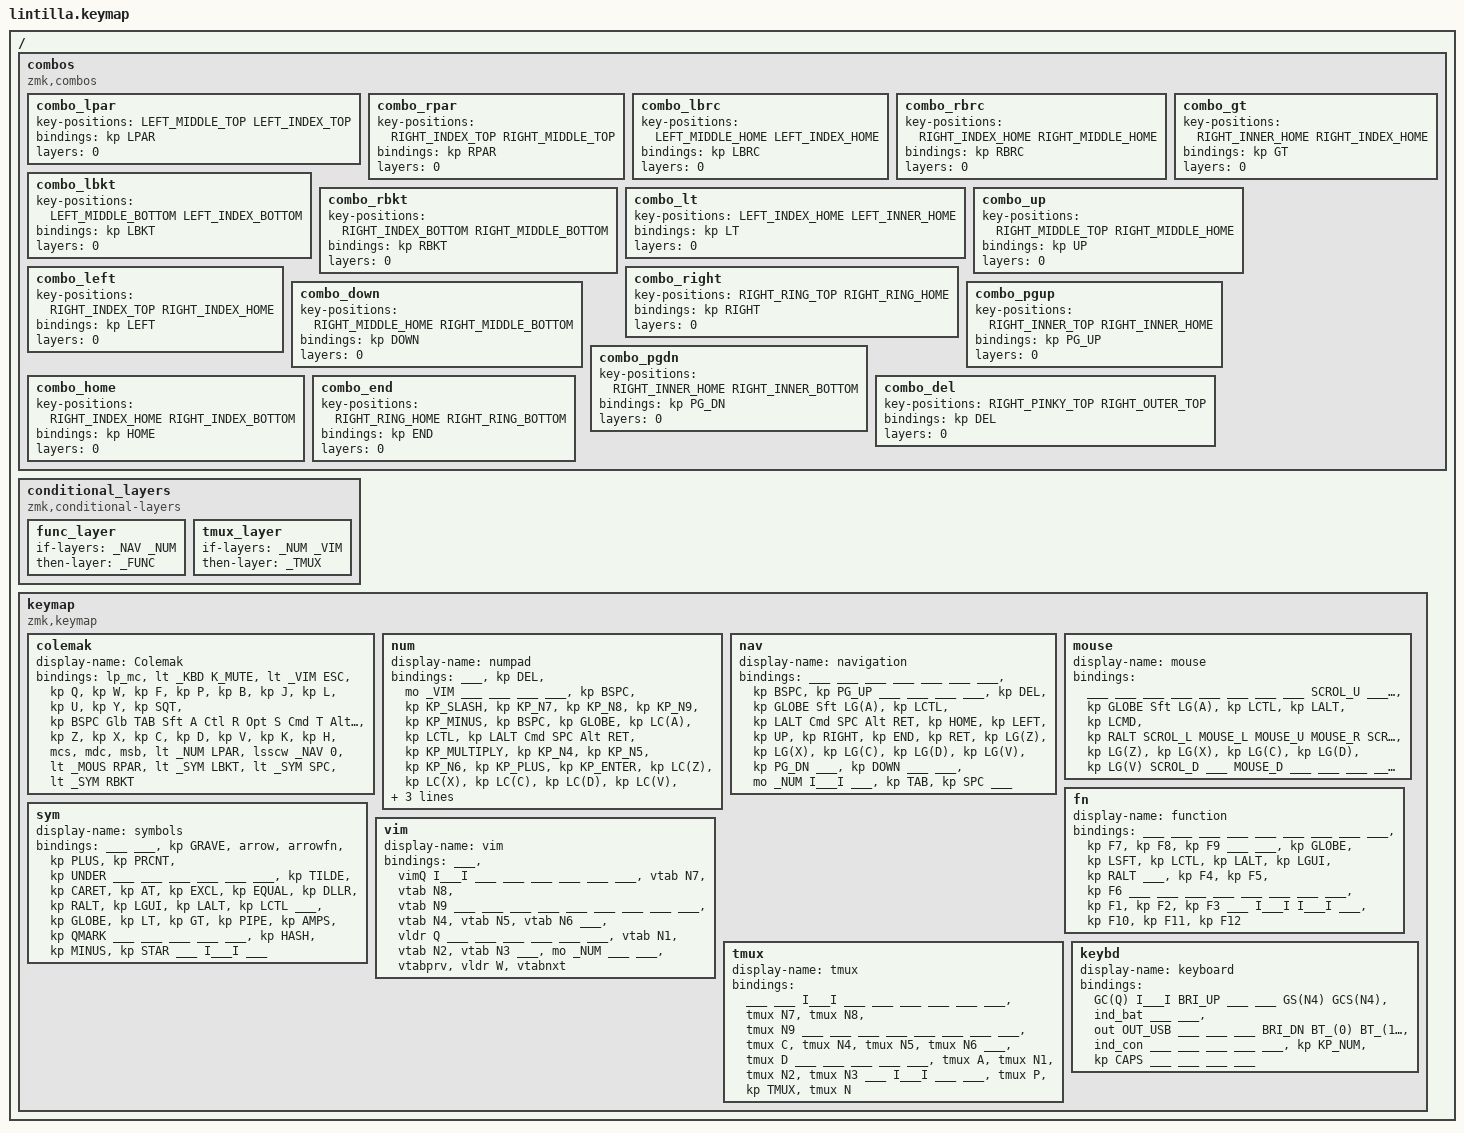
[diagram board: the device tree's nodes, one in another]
#include <behaviors.dtsi>
#include <dt-bindings/zmk/bt.h>
#include <dt-bindings/zmk/keys.h>
#include <dt-bindings/zmk/outputs.h>
#include <dt-bindings/zmk/pointing.h>
#include <behaviors/rgbled_widget.dtsi>
#include "common.keys"

#define _CLMK 0
#define _NUM  1
#define _NAV  2
#define _MOUS 3
#define _FUNC 4
#define _SYM  5
#define _VIM  6
#define _TMUX 7
#define _KBD  8

// Key Positions
//      ┏━━━━┓                                                      ┏━━━━┓
//      ┃  0 ┃                                                      ┃  1 ┃
// ┏━━━━╋━━━━╋━━━━┳━━━━┳━━━━┳━━━━┓              ┏━━━━┳━━━━┳━━━━┳━━━━╋━━━━╋━━━━┓
// ┃  2 ┃  3 ┃  4 ┃  5 ┃  6 ┃  7 ┃              ┃  8 ┃  9 ┃ 10 ┃ 11 ┃ 12 ┃ 13 ┃
// ┣━━━━╋━━━━╋━━━━╋━━━━╋━━━━╋━━━━┫              ┣━━━━╋━━━━╋━━━━╋━━━━╋━━━━╋━━━━┫
// ┃ 14 ┃ 15 ┃ 16 ┃ 17 ┃<18>┃ 19 ┃              ┃ 20 ┃<21>┃ 22 ┃ 23 ┃ 24 ┃ 25 ┃
// ┗━━━━╋━━━━╋━━━━╋━━━━╋━━━━╋━━━━┫              ┣━━━━╋━━━━╋━━━━╋━━━━╋━━━━╋━━━━┛
//      ┃ 26 ┃ 27 ┃ 28 ┃ 29 ┃ 30 ┃              ┃ 31 ┃ 32 ┃ 33 ┃ 34 ┃ 35 ┃
//      ┗━━━━┻━━━━┻━━━━┻┳━━━┻┳━━━┻┳━━━━┓  ┏━━━━┳┻━━━┳┻━━━┳┻━━━━┻━━━━┻━━━━┛
//                      ┃ 36 ┃<37>┃ 38 ┃  ┃ 39 ┃<40>┃ 41 ┃
//                      ┗━━━━┻━━━━┻━━━━┛  ┗━━━━┻━━━━┻━━━━┛
#define LEFT_MACRO 0
#define RIGHT_MACRO 1
#define LEFT_OUTER_TOP 2
#define LEFT_PINKY_TOP 3
#define LEFT_RING_TOP 4
#define LEFT_MIDDLE_TOP 5
#define LEFT_INDEX_TOP 6
#define LEFT_INNER_TOP 7
#define RIGHT_INNER_TOP 8
#define RIGHT_INDEX_TOP 9
#define RIGHT_MIDDLE_TOP 10
#define RIGHT_RING_TOP 11
#define RIGHT_PINKY_TOP 12
#define RIGHT_OUTER_TOP 13
#define LEFT_OUTER_HOME 14
#define LEFT_PINKY_HOME 15
#define LEFT_RING_HOME 16
#define LEFT_MIDDLE_HOME 17
#define LEFT_INDEX_HOME 18
#define LEFT_INNER_HOME 19
#define RIGHT_INNER_HOME 20
#define RIGHT_INDEX_HOME 21
#define RIGHT_MIDDLE_HOME 22
#define RIGHT_RING_HOME 23
#define RIGHT_PINKY_HOME 24
#define RIGHT_OUTER_HOME 25
#define LEFT_PINKY_BOTTOM 26
#define LEFT_RING_BOTTOM 27
#define LEFT_MIDDLE_BOTTOM 28
#define LEFT_INDEX_BOTTOM 29
#define LEFT_INNER_BOTTOM 30
#define RIGHT_INNER_BOTTOM 31
#define RIGHT_INDEX_BOTTOM 32
#define RIGHT_MIDDLE_BOTTOM 33
#define RIGHT_RING_BOTTOM 34
#define RIGHT_PINKY_BOTTOM 35
#define LEFT_THUMB_TUCKY 36
#define LEFT_THUMB_HOME 37
#define LEFT_THUMB_REACHY 38
#define RIGHT_THUMB_REACHY 39
#define RIGHT_THUMB_HOME 40
#define RIGHT_THUMB_TUCKY 41
/ {
    combos {
        compatible = "zmk,combos";
        combo_lpar {
            key-positions = <LEFT_MIDDLE_TOP LEFT_INDEX_TOP>;
            bindings = <&kp LPAR>;
            layers = <0>;
        };
        combo_rpar {
            key-positions = <RIGHT_INDEX_TOP RIGHT_MIDDLE_TOP>;
            bindings = <&kp RPAR>;
            layers = <0>;
        };
        combo_lbrc {
            key-positions = <LEFT_MIDDLE_HOME LEFT_INDEX_HOME>;
            bindings = <&kp LBRC>;
            layers = <0>;
        };
        combo_rbrc {
            key-positions = <RIGHT_INDEX_HOME RIGHT_MIDDLE_HOME>;
            bindings = <&kp RBRC>;
            layers = <0>;
        };
        combo_lbkt {
            key-positions = <LEFT_MIDDLE_BOTTOM LEFT_INDEX_BOTTOM>;
            bindings = <&kp LBKT>;
            layers = <0>;
        };
        combo_rbkt {
            key-positions = <RIGHT_INDEX_BOTTOM RIGHT_MIDDLE_BOTTOM>;
            bindings = <&kp RBKT>;
            layers = <0>;
        };
        combo_lt {
            key-positions = <LEFT_INDEX_HOME LEFT_INNER_HOME>;
            bindings = <&kp LT>;
            layers = <0>;
        };
        combo_gt {
            key-positions = <RIGHT_INNER_HOME RIGHT_INDEX_HOME>;
            bindings = <&kp GT>;
            layers = <0>;
        };
        combo_up {
            key-positions = <RIGHT_MIDDLE_TOP RIGHT_MIDDLE_HOME>;
            bindings = <&kp UP>;
            layers = <0>;
        };
        combo_left {
            key-positions = <RIGHT_INDEX_TOP RIGHT_INDEX_HOME>;
            bindings = <&kp LEFT>;
            layers = <0>;
        };
        combo_right {
            key-positions = <RIGHT_RING_TOP RIGHT_RING_HOME>;
            bindings = <&kp RIGHT>;
            layers = <0>;
        };
        combo_down {
            key-positions = <RIGHT_MIDDLE_HOME RIGHT_MIDDLE_BOTTOM>;
            bindings = <&kp DOWN>;
            layers = <0>;
        };
        combo_pgup {
            key-positions = <RIGHT_INNER_TOP RIGHT_INNER_HOME>;
            bindings = <&kp PG_UP>;
            layers = <0>;
        };
        combo_pgdn {
            key-positions = <RIGHT_INNER_HOME RIGHT_INNER_BOTTOM>;
            bindings = <&kp PG_DN>;
            layers = <0>;
        };
        combo_home {
            key-positions = <RIGHT_INDEX_HOME RIGHT_INDEX_BOTTOM>;
            bindings = <&kp HOME>;
            layers = <0>;
        };
        combo_end {
            key-positions = <RIGHT_RING_HOME RIGHT_RING_BOTTOM>;
            bindings = <&kp END>;
            layers = <0>;
        };
        combo_del {
            key-positions = <RIGHT_PINKY_TOP RIGHT_OUTER_TOP>;
            bindings = <&kp DEL>;
            layers = <0>;
        };
    };

    conditional_layers {
        compatible = "zmk,conditional-layers";
        func_layer {
            if-layers = <_NAV _NUM>;
            then-layer = <_FUNC>;
        };
        tmux_layer {
            if-layers = <_NUM _VIM>;
            then-layer = <_TMUX>;
        };
    };

    keymap {
        compatible = "zmk,keymap";

        colemak {
//                       ┏━━━━━━━━━━━━━━━━━━━━━━━━━┓
            display-name = "Colemak"               ;
//                       ┗━━━━━━━━━━━━━━━━━━━━━━━━━┛
            bindings = <
//         ┏━━━━━━━┓                                                                                          ┏━━━━━━━┓
//         ┃LAUNCHP┃                                                                                          ┃ MUTE  ┃
            &lp_mc                                                                                          &lt _KBD K_MUTE
//         ┃MISSION┃                                                                                          ┃ keybd ┃
// ┏━━━━━━━╋━━━━━━━╋━━━━━━━┳━━━━━━━┳━━━━━━━┳━━━━━━━┓                          ┏━━━━━━━┳━━━━━━━┳━━━━━━━┳━━━━━━━╋━━━━━━━╋━━━━━━━┓
// ┃  ESC  ┃   Q   ┃   W   ┃   F   ┃   P   ┃   B   ┃                          ┃   J   ┃   L   ┃   U   ┃   Y   ┃  ' "  ┃ BKSPC ┃
&lt _VIM ESC &kp Q   &kp W   &kp F   &kp P   &kp B                              &kp J   &kp L   &kp U   &kp Y  &kp SQT &kp BSPC
// ┣━━━━━━━╋━━━━━━━╋━━━━━━━╋━━━━━━━╋━━━━━━━╋━━━━━━━┫                          ┣━━━━━━━╋━━━━━━━╋━━━━━━━╋━━━━━━━╋━━━━━━━╋━━━━━━━┫
// ┃  TAB  ┃   A   ┃   R   ┃   S   ┃   T   ┃   G   ┃                          ┃   M   ┃   N   ┃   E   ┃   I   ┃   O   ┃RETURN ┃
    Glb TAB  Sft A   Ctl R   Opt S   Cmd T   Alt G                              Alt M   Cmd N   Opt E   Ctl I   Sft O  Glb RET
// ┃ Globe ┃ Shift ┃ Ctrl  ┃  Opt  ┃  Cmd  ┃ R Alt ┃                          ┃ R Alt ┃  Cmd  ┃  Opt  ┃ Ctrl  ┃ Shift ┃ Globe ┃
// ┗━━━━━━━╋━━━━━━━╋━━━━━━━╋━━━━━━━╋━━━━━━━╋━━━━━━━┫                          ┣━━━━━━━╋━━━━━━━╋━━━━━━━╋━━━━━━━╋━━━━━━━╋━━━━━━━┛
//         ┃   Z   ┃   X   ┃   C   ┃   D   ┃   V   ┃                          ┃   K   ┃   H   ┃  , ;  ┃  . :  ┃  / \  ┃
             &kp Z   &kp X   &kp C   &kp D   &kp V                              &kp K   &kp H   &mcs    &mdc    &msb
//         ┗━━━━━━━┻━━━━━━━┻━━━━━━━┻━━━┳━━━┻━━━┳━━━┻━━━┳━━━━━━━┓  ┏━━━━━━━┳━━━┻━━━┳━━━┻━━━┳━━━┻━━━━━━━┻━━━━━━━┻━━━━━━━┛
//                                     ┃ ( num ┃ SHIFT ┃ ) mous┃  ┃  [ {  ┃ SPACE ┃  ] }  ┃
                      &lt _NUM LPAR &lsscw _NAV 0 &lt _MOUS RPAR  &lt _SYM LBKT &lt _SYM SPC &lt _SYM RBKT
//                                     ┗━━━━━━━┫  nav  ┣━━━━━━━┛  ┗━━━━━━━┫  sym  ┣━━━━━━━┛
//                                             ┗━━━━━━━┛                  ┗━━━━━━━┛
            >;
        };

        num {
//                       ┏━━━━━━━━━━━━━━━━━━━━━━━━━┓
            display-name = "numpad"                ;
//                       ┗━━━━━━━━━━━━━━━━━━━━━━━━━┛
            bindings = <
//         ┏━━━━━━━┓                                                                                          ┏━━━━━━━┓
//         ┃       ┃                                                                                          ┃  DEL  ┃
              ___                                                                                              &kp DEL
// ┏━━━━━━━╋━━━━━━━╋━━━━━━━┳━━━━━━━┳━━━━━━━┳━━━━━━━┓                          ┏━━━━━━━┳━━━━━━━┳━━━━━━━┳━━━━━━━╋━━━━━━━╋━━━━━━━┓
// ┃ tmux  ┃       ┃       ┃       ┃       ┃ BKSPC ┃                          ┃   /   ┃   7   ┃   8   ┃   9   ┃   -   ┃ BKSPC ┃
   &mo _VIM   ___     ___     ___     ___  &kp BSPC                &kp KP_SLASH &kp KP_N7 &kp KP_N8 &kp KP_N9 &kp KP_MINUS &kp BSPC
// ┣━━━━━━━╋━━━━━━━╋━━━━━━━╋━━━━━━━╋━━━━━━━╋━━━━━━━┫                          ┣━━━━━━━╋━━━━━━━╋━━━━━━━╋━━━━━━━╋━━━━━━━╋━━━━━━━┫
// ┃       ┃ CtrlA ┃       ┃       ┃ SPACE ┃RETURN ┃                          ┃   *   ┃   4   ┃   5   ┃   6   ┃   +   ┃RETURN ┃
&kp GLOBE &kp LC(A) &kp LCTL &kp LALT Cmd SPC Alt RET             &kp KP_MULTIPLY &kp KP_N4 &kp KP_N5 &kp KP_N6 &kp KP_PLUS &kp KP_ENTER
// ┃ Globe ┃       ┃ Ctrl  ┃  Opt  ┃  Cmd  ┃ R Alt ┃                          ┃       ┃       ┃       ┃       ┃       ┃       ┃
// ┗━━━━━━━╋━━━━━━━╋━━━━━━━╋━━━━━━━╋━━━━━━━╋━━━━━━━┫                          ┣━━━━━━━╋━━━━━━━╋━━━━━━━╋━━━━━━━╋━━━━━━━╋━━━━━━━┛
//         ┃ CtrlZ ┃ CtrlX ┃ CtrlC ┃ CtrlD ┃ CtrlV ┃                          ┃   :   ┃   1   ┃   2   ┃   3   ┃   =   ┃
         &kp LC(Z) &kp LC(X) &kp LC(C) &kp LC(D) &kp LC(V)              &kp COLON &kp KP_N1 &kp KP_N2 &kp KP_N3 &kp KP_EQUAL
//         ┗━━━━━━━┻━━━━━━━┻━━━━━━━┻━━━┳━━━┻━━━┳━━━┻━━━┳━━━━━━━┓  ┏━━━━━━━┳━━━┻━━━┳━━━┻━━━┳━━━┻━━━━━━━┻━━━━━━━┻━━━━━━━┛
//                                     ┃ ##### ┃       ┃       ┃  ┃   ,   ┃   0   ┃   .   ┃
                                         I___I  &mo _NAV  ___    &kp COMMA &kp KP_N0 &kp DOT
//                                     ┗━━━━━━━┫  fn   ┣━━━━━━━┛  ┗━━━━━━━┫       ┣━━━━━━━┛
//                                             ┗━━━━━━━┛                  ┗━━━━━━━┛
            >;
        };

        nav {
//                       ┏━━━━━━━━━━━━━━━━━━━━━━━━━┓
            display-name = "navigation"            ;
//                       ┗━━━━━━━━━━━━━━━━━━━━━━━━━┛
            bindings = <
//         ┏━━━━━━━┓                                                                                          ┏━━━━━━━┓
//         ┃       ┃                                                                                          ┃       ┃
              ___                                                                                                ___
// ┏━━━━━━━╋━━━━━━━╋━━━━━━━┳━━━━━━━┳━━━━━━━┳━━━━━━━┓                          ┏━━━━━━━┳━━━━━━━┳━━━━━━━┳━━━━━━━╋━━━━━━━╋━━━━━━━┓
// ┃       ┃       ┃       ┃       ┃       ┃ BKSPC ┃                          ┃ Pg Up ┃       ┃       ┃       ┃       ┃  DEL  ┃
      ___     ___     ___     ___     ___  &kp BSPC                           &kp PG_UP  ___     ___     ___     ___   &kp DEL
// ┣━━━━━━━╋━━━━━━━╋━━━━━━━╋━━━━━━━╋━━━━━━━╋━━━━━━━┫                          ┣━━━━━━━╋━━━━━━━╋━━━━━━━╋━━━━━━━╋━━━━━━━╋━━━━━━━┫
// ┃       ┃ Cmd A ┃       ┃       ┃ SPACE ┃RETURN ┃                          ┃ Home  ┃ Left  ┃  Up   ┃ Right ┃  End  ┃RETURN ┃
&kp GLOBE Sft LG(A) &kp LCTL &kp LALT Cmd SPC Alt RET                        &kp HOME &kp LEFT &kp UP &kp RIGHT &kp END &kp RET
// ┃ Globe ┃ Shift ┃ Ctrl  ┃  Opt  ┃  Cmd  ┃ R Alt ┃                          ┃       ┃       ┃       ┃       ┃       ┃       ┃
// ┗━━━━━━━╋━━━━━━━╋━━━━━━━╋━━━━━━━╋━━━━━━━╋━━━━━━━┫                          ┣━━━━━━━╋━━━━━━━╋━━━━━━━╋━━━━━━━╋━━━━━━━╋━━━━━━━┛
//         ┃ Cmd Z ┃ Cmd X ┃ Cmd C ┃ Cmd D ┃ Cmd V ┃                          ┃ Pg Dn ┃       ┃ Down  ┃       ┃       ┃
         &kp LG(Z) &kp LG(X) &kp LG(C) &kp LG(D) &kp LG(V)                    &kp PG_DN  ___   &kp DOWN  ___     ___
//         ┗━━━━━━━┻━━━━━━━┻━━━━━━━┻━━━┳━━━┻━━━┳━━━┻━━━┳━━━━━━━┓  ┏━━━━━━━┳━━━┻━━━┳━━━┻━━━┳━━━┻━━━━━━━┻━━━━━━━┻━━━━━━━┛
//                                     ┃  fn   ┃ ##### ┃       ┃  ┃  TAB  ┃ SPACE ┃       ┃
                                        &mo _NUM I___I    ___      &kp TAB &kp SPC   ___
//                                     ┗━━━━━━━┫       ┣━━━━━━━┛  ┗━━━━━━━┫       ┣━━━━━━━┛
//                                             ┗━━━━━━━┛                  ┗━━━━━━━┛
            >;
        };

        mouse {
//                       ┏━━━━━━━━━━━━━━━━━━━━━━━━━┓
            display-name = "mouse"                 ;
//                       ┗━━━━━━━━━━━━━━━━━━━━━━━━━┛
            bindings = <
//         ┏━━━━━━━┓                                                                                          ┏━━━━━━━┓
//         ┃       ┃                                                                                          ┃       ┃
              ___                                                                                                ___
// ┏━━━━━━━╋━━━━━━━╋━━━━━━━┳━━━━━━━┳━━━━━━━┳━━━━━━━┓                          ┏━━━━━━━┳━━━━━━━┳━━━━━━━┳━━━━━━━╋━━━━━━━╋━━━━━━━┓
// ┃       ┃       ┃       ┃       ┃       ┃       ┃                          ┃ScrolUp┃       ┃       ┃       ┃       ┃       ┃
      ___     ___     ___     ___     ___     ___                              SCROL_U   ___     ___     ___     ___     ___
// ┣━━━━━━━╋━━━━━━━╋━━━━━━━╋━━━━━━━╋━━━━━━━╋━━━━━━━┫                          ┣━━━━━━━╋━━━━━━━╋━━━━━━━╋━━━━━━━╋━━━━━━━╋━━━━━━━┫
// ┃       ┃ Cmd A ┃       ┃       ┃       ┃       ┃                          ┃ScrolLt┃ Left  ┃  Up   ┃ Right ┃ScrolRt┃       ┃
&kp GLOBE Sft LG(A) &kp LCTL &kp LALT &kp LCMD &kp RALT                        SCROL_L MOUSE_L MOUSE_U MOUSE_R SCROL_R   ___
// ┃ Globe ┃ Shift ┃ Ctrl  ┃  Opt  ┃  Cmd  ┃ R Alt ┃                          ┃       ┃       ┃       ┃       ┃       ┃       ┃
// ┗━━━━━━━╋━━━━━━━╋━━━━━━━╋━━━━━━━╋━━━━━━━╋━━━━━━━┫                          ┣━━━━━━━╋━━━━━━━╋━━━━━━━╋━━━━━━━╋━━━━━━━╋━━━━━━━┛
//         ┃ Cmd Z ┃ Cmd X ┃ Cmd C ┃ Cmd D ┃ Cmd V ┃                          ┃ScrolDn┃       ┃ Down  ┃       ┃       ┃
         &kp LG(Z) &kp LG(X) &kp LG(C) &kp LG(D) &kp LG(V)                     SCROL_D   ___   MOUSE_D   ___     ___
//         ┗━━━━━━━┻━━━━━━━┻━━━━━━━┻━━━┳━━━┻━━━┳━━━┻━━━┳━━━━━━━┓  ┏━━━━━━━┳━━━┻━━━┳━━━┻━━━┳━━━┻━━━━━━━┻━━━━━━━┻━━━━━━━┛
//                                     ┃       ┃       ┃ ##### ┃  ┃       ┃l click┃r click┃
                                          ___     ___    I___I       ___   CLICK_L CLICK_R
//                                     ┗━━━━━━━┫       ┣━━━━━━━┛  ┗━━━━━━━┫       ┣━━━━━━━┛
//                                             ┗━━━━━━━┛                  ┗━━━━━━━┛
            >;
        };

        fn {
//                       ┏━━━━━━━━━━━━━━━━━━━━━━━━━┓
            display-name = "function"              ;
//                       ┗━━━━━━━━━━━━━━━━━━━━━━━━━┛
            bindings = <
//         ┏━━━━━━━┓                                                                                          ┏━━━━━━━┓
//         ┃       ┃                                                                                          ┃       ┃
              ___                                                                                                ___
// ┏━━━━━━━╋━━━━━━━╋━━━━━━━┳━━━━━━━┳━━━━━━━┳━━━━━━━┓                          ┏━━━━━━━┳━━━━━━━┳━━━━━━━┳━━━━━━━╋━━━━━━━╋━━━━━━━┓
// ┃       ┃       ┃       ┃       ┃       ┃       ┃                          ┃       ┃  F7   ┃  F8   ┃  F9   ┃       ┃       ┃
      ___     ___     ___     ___     ___     ___                                ___   &kp F7  &kp F8  &kp F9    ___     ___
// ┣━━━━━━━╋━━━━━━━╋━━━━━━━╋━━━━━━━╋━━━━━━━╋━━━━━━━┫                          ┣━━━━━━━╋━━━━━━━╋━━━━━━━╋━━━━━━━╋━━━━━━━╋━━━━━━━┫
// ┃ Globe ┃ Shift ┃ Ctrl  ┃  Opt  ┃  Cmd  ┃ R Alt ┃                          ┃       ┃  F4   ┃  F5   ┃  F6   ┃       ┃       ┃
&kp GLOBE &kp LSFT &kp LCTL &kp LALT &kp LGUI &kp RALT                           ___   &kp F4  &kp F5  &kp F6    ___     ___
// ┗━━━━━━━╋━━━━━━━╋━━━━━━━╋━━━━━━━╋━━━━━━━╋━━━━━━━┫                          ┣━━━━━━━╋━━━━━━━╋━━━━━━━╋━━━━━━━╋━━━━━━━╋━━━━━━━┛
//         ┃       ┃       ┃       ┃       ┃       ┃                          ┃       ┃  F1   ┃  F2   ┃  F3   ┃       ┃
              ___     ___     ___     ___     ___                                ___   &kp F1  &kp F2  &kp F3    ___
//         ┗━━━━━━━┻━━━━━━━┻━━━━━━━┻━━━┳━━━┻━━━┳━━━┻━━━┳━━━━━━━┓  ┏━━━━━━━┳━━━┻━━━┳━━━┻━━━┳━━━┻━━━━━━━┻━━━━━━━┻━━━━━━━┛
//                                     ┃ ##### ┃ ##### ┃       ┃  ┃  F10  ┃  F11  ┃  F12  ┃
                                         I___I   I___I    ___      &kp F10 &kp F11 &kp F12
//                                     ┗━━━━━━━┫       ┣━━━━━━━┛  ┗━━━━━━━┫       ┣━━━━━━━┛
//                                             ┗━━━━━━━┛                  ┗━━━━━━━┛
            >;
        };

        sym {
//                       ┏━━━━━━━━━━━━━━━━━━━━━━━━━┓
            display-name = "symbols"               ;
//                       ┗━━━━━━━━━━━━━━━━━━━━━━━━━┛
            bindings = <
//         ┏━━━━━━━┓                                                                                          ┏━━━━━━━┓
//         ┃       ┃                                                                                          ┃       ┃
              ___                                                                                                ___
// ┏━━━━━━━╋━━━━━━━╋━━━━━━━┳━━━━━━━┳━━━━━━━┳━━━━━━━┓                          ┏━━━━━━━┳━━━━━━━┳━━━━━━━┳━━━━━━━╋━━━━━━━╋━━━━━━━┓
// ┃   `   ┃  =>   ┃()=>{|}┃   +   ┃   %   ┃   _   ┃                          ┃       ┃       ┃       ┃       ┃       ┃       ┃
&kp GRAVE &arrow &arrowfn &kp PLUS &kp PRCNT &kp UNDER                           ___     ___     ___     ___     ___     ___
// ┣━━━━━━━╋━━━━━━━╋━━━━━━━╋━━━━━━━╋━━━━━━━╋━━━━━━━┫                          ┣━━━━━━━╋━━━━━━━╋━━━━━━━╋━━━━━━━╋━━━━━━━╋━━━━━━━┫
// ┃   ~   ┃   ^   ┃   @   ┃   !   ┃   =   ┃   $   ┃                          ┃ R Alt ┃  Cmd  ┃  Opt  ┃ Ctrl  ┃       ┃ Globe ┃
&kp TILDE &kp CARET &kp AT &kp EXCL &kp EQUAL &kp DLLR                      &kp RALT &kp LGUI &kp LALT &kp LCTL  ___  &kp GLOBE
// ┗━━━━━━━╋━━━━━━━╋━━━━━━━╋━━━━━━━╋━━━━━━━╋━━━━━━━┫                          ┣━━━━━━━╋━━━━━━━╋━━━━━━━╋━━━━━━━╋━━━━━━━╋━━━━━━━┛
//         ┃   <   ┃   >   ┃   |   ┃   &   ┃   ?   ┃                          ┃       ┃       ┃       ┃       ┃       ┃
             &kp LT &kp GT &kp PIPE &kp AMPS &kp QMARK                           ___     ___     ___     ___     ___
//         ┗━━━━━━━┻━━━━━━━┻━━━━━━━┻━━━┳━━━┻━━━┳━━━┻━━━┳━━━━━━━┓  ┏━━━━━━━┳━━━┻━━━┳━━━┻━━━┳━━━┻━━━━━━━┻━━━━━━━┻━━━━━━━┛
//                                     ┃   #   ┃   -   ┃   *   ┃  ┃       ┃ ##### ┃       ┃
                                      &kp HASH &kp MINUS &kp STAR    ___    I___I    ___
//                                     ┗━━━━━━━┫       ┣━━━━━━━┛  ┗━━━━━━━┫       ┣━━━━━━━┛
//                                             ┗━━━━━━━┛                  ┗━━━━━━━┛
            >;
        };

        vim {
//                       ┏━━━━━━━━━━━━━━━━━━━━━━━━━┓
            display-name = "vim"                   ;
//                       ┗━━━━━━━━━━━━━━━━━━━━━━━━━┛
            bindings = <
//         ┏━━━━━━━┓                                                                                          ┏━━━━━━━┓
//         ┃       ┃                                                                                          ┃ QUIT  ┃
              ___                                                                                               &vimQ
// ┏━━━━━━━╋━━━━━━━╋━━━━━━━┳━━━━━━━┳━━━━━━━┳━━━━━━━┓                          ┏━━━━━━━┳━━━━━━━┳━━━━━━━┳━━━━━━━╋━━━━━━━╋━━━━━━━┓
// ┃ ##### ┃       ┃       ┃       ┃       ┃       ┃                          ┃       ┃ tab 7 ┃ tab 8 ┃ tab 9 ┃       ┃       ┃
     I___I    ___     ___     ___     ___     ___                                ___ &vtab N7 &vtab N8 &vtab N9  ___     ___
// ┣━━━━━━━╋━━━━━━━╋━━━━━━━╋━━━━━━━╋━━━━━━━╋━━━━━━━┫                          ┣━━━━━━━╋━━━━━━━╋━━━━━━━╋━━━━━━━╋━━━━━━━╋━━━━━━━┫
// ┃       ┃       ┃       ┃       ┃       ┃       ┃                          ┃       ┃ tab 4 ┃ tab 5 ┃ tab 6 ┃       ┃ exit  ┃
      ___     ___     ___     ___     ___     ___                                ___ &vtab N4 &vtab N5 &vtab N6  ___   &vldr Q
// ┗━━━━━━━╋━━━━━━━╋━━━━━━━╋━━━━━━━╋━━━━━━━╋━━━━━━━┫                          ┣━━━━━━━╋━━━━━━━╋━━━━━━━╋━━━━━━━╋━━━━━━━╋━━━━━━━┛
//         ┃       ┃       ┃       ┃       ┃       ┃                          ┃       ┃ tab 1 ┃ tab 2 ┃ tab 3 ┃       ┃
              ___     ___     ___     ___     ___                                ___ &vtab N1 &vtab N2 &vtab N3  ___
//         ┗━━━━━━━┻━━━━━━━┻━━━━━━━┻━━━┳━━━┻━━━┳━━━┻━━━┳━━━━━━━┓  ┏━━━━━━━┳━━━┻━━━┳━━━┻━━━┳━━━┻━━━━━━━┻━━━━━━━┻━━━━━━━┛
//                                     ┃ tmux  ┃       ┃       ┃  ┃prevtab┃ save  ┃nexttab┃
                                       &mo _NUM   ___     ___     &vtabprv &vldr W &vtabnxt
//                                     ┗━━━━━━━┫       ┣━━━━━━━┛  ┗━━━━━━━┫       ┣━━━━━━━┛
//                                             ┗━━━━━━━┛                  ┗━━━━━━━┛
            >;
        };

        tmux {
//                       ┏━━━━━━━━━━━━━━━━━━━━━━━━━┓
            display-name = "tmux"                  ;
//                       ┗━━━━━━━━━━━━━━━━━━━━━━━━━┛
            bindings = <
//         ┏━━━━━━━┓                                                                                          ┏━━━━━━━┓
//         ┃       ┃                                                                                          ┃       ┃
              ___                                                                                                ___
// ┏━━━━━━━╋━━━━━━━╋━━━━━━━┳━━━━━━━┳━━━━━━━┳━━━━━━━┓                          ┏━━━━━━━┳━━━━━━━┳━━━━━━━┳━━━━━━━╋━━━━━━━╋━━━━━━━┓
// ┃ ##### ┃       ┃       ┃       ┃       ┃       ┃                          ┃       ┃ tab 7 ┃ tab 8 ┃ tab 9 ┃       ┃       ┃
     I___I    ___     ___     ___     ___     ___                                ___ &tmux N7 &tmux N8 &tmux N9  ___     ___
// ┣━━━━━━━╋━━━━━━━╋━━━━━━━╋━━━━━━━╋━━━━━━━╋━━━━━━━┫                          ┣━━━━━━━╋━━━━━━━╋━━━━━━━╋━━━━━━━╋━━━━━━━╋━━━━━━━┫
// ┃       ┃       ┃       ┃       ┃       ┃       ┃                          ┃  new  ┃ tab 4 ┃ tab 5 ┃ tab 6 ┃       ┃ close ┃
      ___     ___     ___     ___     ___     ___                            &tmux C &tmux N4 &tmux N5 &tmux N6  ___   &tmux D
// ┗━━━━━━━╋━━━━━━━╋━━━━━━━╋━━━━━━━╋━━━━━━━╋━━━━━━━┫                          ┣━━━━━━━╋━━━━━━━╋━━━━━━━╋━━━━━━━╋━━━━━━━╋━━━━━━━┛
//         ┃       ┃       ┃       ┃       ┃       ┃                          ┃rename ┃ tab 1 ┃ tab 2 ┃ tab 3 ┃       ┃
              ___     ___     ___     ___     ___                            &tmux A &tmux N1 &tmux N2 &tmux N3  ___
//         ┗━━━━━━━┻━━━━━━━┻━━━━━━━┻━━━┳━━━┻━━━┳━━━┻━━━┳━━━━━━━┓  ┏━━━━━━━┳━━━┻━━━┳━━━┻━━━┳━━━┻━━━━━━━┻━━━━━━━┻━━━━━━━┛
//                                     ┃ ##### ┃       ┃       ┃  ┃prevtab┃tmuxldr┃nexttab┃
                                         I___I    ___     ___     &tmux P &kp TMUX &tmux N
//                                     ┗━━━━━━━┫       ┣━━━━━━━┛  ┗━━━━━━━┫       ┣━━━━━━━┛
//                                             ┗━━━━━━━┛                  ┗━━━━━━━┛
            >;
        };

        keybd {
//                       ┏━━━━━━━━━━━━━━━━━━━━━━━━━┓
            display-name = "keyboard"              ;
//                       ┗━━━━━━━━━━━━━━━━━━━━━━━━━┛
            bindings = <
//         ┏━━━━━━━┓                                                                                          ┏━━━━━━━┓
//         ┃scrnlok┃                                                                                          ┃ ##### ┃
             GC(Q)                                                                                              I___I
// ┏━━━━━━━╋━━━━━━━╋━━━━━━━┳━━━━━━━┳━━━━━━━┳━━━━━━━┓                          ┏━━━━━━━┳━━━━━━━┳━━━━━━━┳━━━━━━━╋━━━━━━━╋━━━━━━━┓
// ┃ brt + ┃       ┃       ┃scrnsht┃scrn cp┃battery┃                          ┃       ┃       ┃  USB  ┃       ┃       ┃       ┃
     BRI_UP   ___     ___   GS(N4)  GCS(N4) &ind_bat                             ___     ___ &out OUT_USB ___    ___     ___
// ┣━━━━━━━╋━━━━━━━╋━━━━━━━╋━━━━━━━╋━━━━━━━╋━━━━━━━┫                          ┣━━━━━━━╋━━━━━━━╋━━━━━━━╋━━━━━━━╋━━━━━━━╋━━━━━━━┫
// ┃ brt - ┃  BT1  ┃  BT2  ┃  BT3  ┃  BT4  ┃  BT5  ┃                          ┃       ┃       ┃       ┃       ┃       ┃       ┃
     BRI_DN  BT_(0)  BT_(1)  BT_(2)  BT_(3)  BT_(4)                              ___     ___     ___     ___     ___     ___
// ┗━━━━━━━╋━━━━━━━╋━━━━━━━╋━━━━━━━╋━━━━━━━╋━━━━━━━┫                          ┣━━━━━━━╋━━━━━━━╋━━━━━━━╋━━━━━━━╋━━━━━━━╋━━━━━━━┛
//         ┃       ┃micmute┃ vol - ┃ vol + ┃connect┃                          ┃       ┃       ┃       ┃       ┃       ┃
              ___   HYPR(M)  VOL_DN  VOL_UP &ind_con                             ___     ___     ___     ___     ___
//         ┗━━━━━━━┻━━━━━━━┻━━━━━━━┻━━━┳━━━┻━━━┳━━━┻━━━┳━━━━━━━┓  ┏━━━━━━━┳━━━┻━━━┳━━━┻━━━┳━━━┻━━━━━━━┻━━━━━━━┻━━━━━━━┛
//                                     ┃numlock┃capslok┃       ┃  ┃       ┃       ┃       ┃
                                      &kp KP_NUM &kp CAPS ___        ___     ___     ___
//                                     ┗━━━━━━━┫       ┣━━━━━━━┛  ┗━━━━━━━┫       ┣━━━━━━━┛
//                                             ┗━━━━━━━┛                  ┗━━━━━━━┛
            >;
        };
    };
};

// vim: expandtab softtabstop=4 shiftwidth=4 filetype=dts
